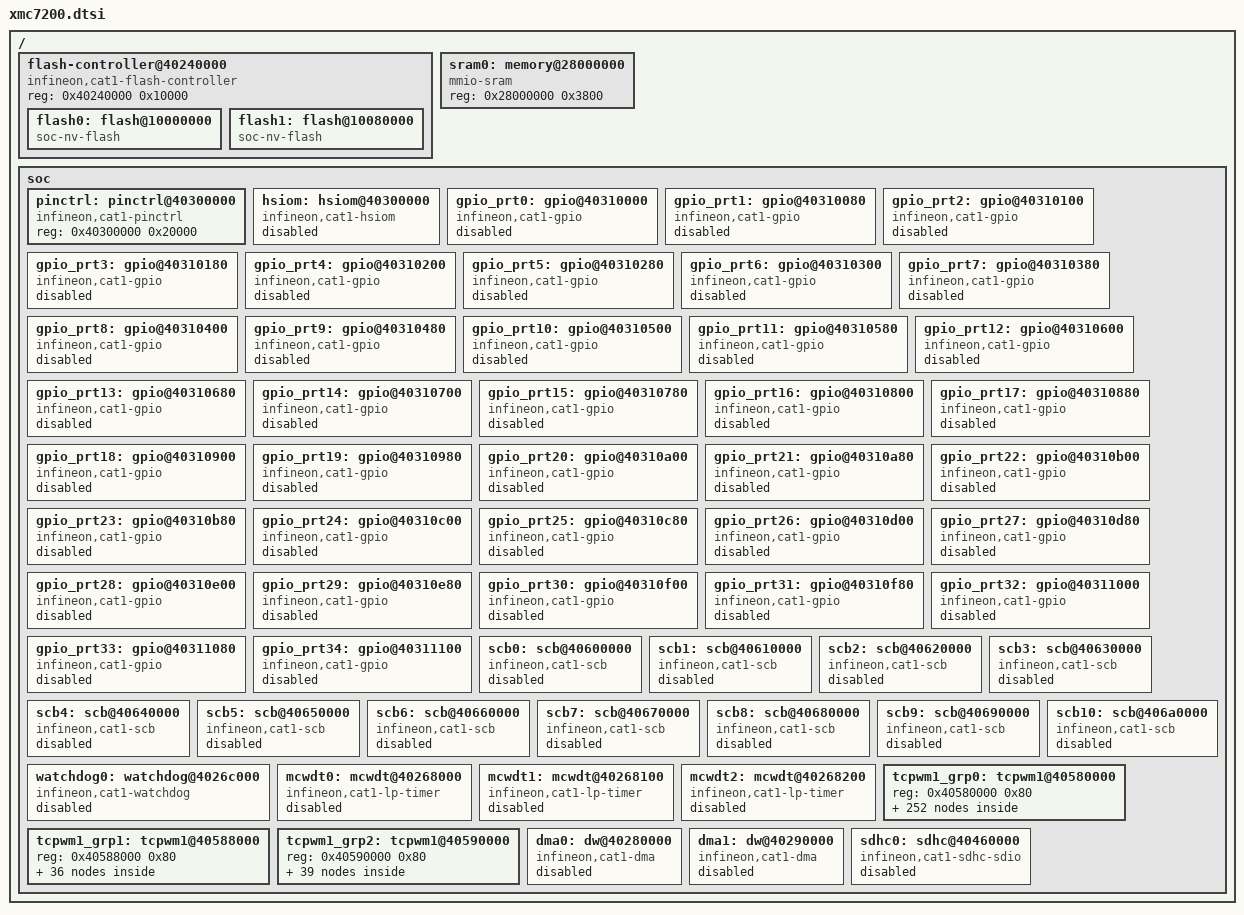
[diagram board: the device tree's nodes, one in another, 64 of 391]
/*
 * Copyright (c) 2023 Cypress Semiconductor Corporation (an Infineon company) or
 * an affiliate of Cypress Semiconductor Corporation
 *
 * SPDX-License-Identifier: Apache-2.0
 */

#include <mem.h>

/ {
	flash-controller@40240000 {
		compatible = "infineon,cat1-flash-controller";
		reg = <0x40240000 0x10000>;
		#address-cells = <1>;
		#size-cells = <1>;

		flash0: flash@10000000 {
			compatible = "soc-nv-flash";
			reg = <0x10000000 0x80000>;
			write-block-size = <512>;
			erase-block-size = <512>;
		};

		flash1: flash@10080000 {
			compatible = "soc-nv-flash";
			reg = <0x10080000 0x200000>;
			write-block-size = <512>;
			erase-block-size = <512>;
		};
	};

	/* 0x0000000028000800  _base_SRAM_CM0P =
	 * ((sram_base_address + sram_start_reserve) + sram_private_for_srom)
	 * TODO: Where better to keep srom private
	 */
	sram0: memory@28000000 {
		compatible = "mmio-sram";
		reg = <0x28000000 0x3800>;
	};

	soc {
		pinctrl: pinctrl@40300000 {
			compatible = "infineon,cat1-pinctrl";
			reg = <0x40300000 0x20000>;
		};

		hsiom: hsiom@40300000 {
			compatible = "infineon,cat1-hsiom";
			reg = <0x40300000 0x4000>;
			system-interrupts = <21 6>, <20 6>;
			status = "disabled";
		};

		gpio_prt0: gpio@40310000 {
			compatible = "infineon,cat1-gpio";
			reg = <0x40310000 0x80>;
			system-interrupts = <22 2>;
			gpio-controller;
			ngpios = <4>;
			status = "disabled";
			#gpio-cells = <2>;
		};

		gpio_prt1: gpio@40310080 {
			compatible = "infineon,cat1-gpio";
			reg = <0x40310080 0x80>;
			system-interrupts = <23 2>;
			gpio-controller;
			ngpios = <7>;
			status = "disabled";
			#gpio-cells = <2>;
		};

		gpio_prt2: gpio@40310100 {
			compatible = "infineon,cat1-gpio";
			reg = <0x40310100 0x80>;
			system-interrupts = <24 2>;
			gpio-controller;
			ngpios = <8>;
			status = "disabled";
			#gpio-cells = <2>;
		};

		gpio_prt3: gpio@40310180 {
			compatible = "infineon,cat1-gpio";
			reg = <0x40310180 0x80>;
			system-interrupts = <25 2>;
			gpio-controller;
			ngpios = <8>;
			status = "disabled";
			#gpio-cells = <2>;
		};

		gpio_prt4: gpio@40310200 {
			compatible = "infineon,cat1-gpio";
			reg = <0x40310200 0x80>;
			system-interrupts = <26 2>;
			gpio-controller;
			ngpios = <7>;
			status = "disabled";
			#gpio-cells = <2>;
		};

		gpio_prt5: gpio@40310280 {
			compatible = "infineon,cat1-gpio";
			reg = <0x40310280 0x80>;
			system-interrupts = <27 2>;
			gpio-controller;
			ngpios = <6>;
			status = "disabled";
			#gpio-cells = <2>;
		};

		gpio_prt6: gpio@40310300 {
			compatible = "infineon,cat1-gpio";
			reg = <0x40310300 0x80>;
			system-interrupts = <28 2>;
			gpio-controller;
			ngpios = <8>;
			status = "disabled";
			#gpio-cells = <2>;
		};

		gpio_prt7: gpio@40310380 {
			compatible = "infineon,cat1-gpio";
			reg = <0x40310380 0x80>;
			system-interrupts = <29 2>;
			gpio-controller;
			ngpios = <8>;
			status = "disabled";
			#gpio-cells = <2>;
		};

		gpio_prt8: gpio@40310400 {
			compatible = "infineon,cat1-gpio";
			reg = <0x40310400 0x80>;
			system-interrupts = <30 2>;
			gpio-controller;
			ngpios = <5>;
			status = "disabled";
			#gpio-cells = <2>;
		};

		gpio_prt9: gpio@40310480 {
			compatible = "infineon,cat1-gpio";
			reg = <0x40310480 0x80>;
			system-interrupts = <31 2>;
			gpio-controller;
			ngpios = <4>;
			status = "disabled";
			#gpio-cells = <2>;
		};

		gpio_prt10: gpio@40310500 {
			compatible = "infineon,cat1-gpio";
			reg = <0x40310500 0x80>;
			system-interrupts = <32 2>;
			gpio-controller;
			ngpios = <8>;
			status = "disabled";
			#gpio-cells = <2>;
		};

		gpio_prt11: gpio@40310580 {
			compatible = "infineon,cat1-gpio";
			reg = <0x40310580 0x80>;
			system-interrupts = <33 2>;
			gpio-controller;
			ngpios = <3>;
			status = "disabled";
			#gpio-cells = <2>;
		};

		gpio_prt12: gpio@40310600 {
			compatible = "infineon,cat1-gpio";
			reg = <0x40310600 0x80>;
			system-interrupts = <34 2>;
			gpio-controller;
			ngpios = <8>;
			status = "disabled";
			#gpio-cells = <2>;
		};

		gpio_prt13: gpio@40310680 {
			compatible = "infineon,cat1-gpio";
			reg = <0x40310680 0x80>;
			system-interrupts = <35 2>;
			gpio-controller;
			ngpios = <8>;
			status = "disabled";
			#gpio-cells = <2>;
		};

		gpio_prt14: gpio@40310700 {
			compatible = "infineon,cat1-gpio";
			reg = <0x40310700 0x80>;
			system-interrupts = <36 2>;
			gpio-controller;
			ngpios = <8>;
			status = "disabled";
			#gpio-cells = <2>;
		};

		gpio_prt15: gpio@40310780 {
			compatible = "infineon,cat1-gpio";
			reg = <0x40310780 0x80>;
			system-interrupts = <37 2>;
			gpio-controller;
			ngpios = <4>;
			status = "disabled";
			#gpio-cells = <2>;
		};

		gpio_prt16: gpio@40310800 {
			compatible = "infineon,cat1-gpio";
			reg = <0x40310800 0x80>;
			system-interrupts = <38 2>;
			gpio-controller;
			ngpios = <8>;
			status = "disabled";
			#gpio-cells = <2>;
		};

		gpio_prt17: gpio@40310880 {
			compatible = "infineon,cat1-gpio";
			reg = <0x40310880 0x80>;
			system-interrupts = <39 2>;
			gpio-controller;
			ngpios = <8>;
			status = "disabled";
			#gpio-cells = <2>;
		};

		gpio_prt18: gpio@40310900 {
			compatible = "infineon,cat1-gpio";
			reg = <0x40310900 0x80>;
			system-interrupts = <40 2>;
			gpio-controller;
			ngpios = <8>;
			status = "disabled";
			#gpio-cells = <2>;
		};

		gpio_prt19: gpio@40310980 {
			compatible = "infineon,cat1-gpio";
			reg = <0x40310980 0x80>;
			system-interrupts = <41 2>;
			gpio-controller;
			ngpios = <5>;
			status = "disabled";
			#gpio-cells = <2>;
		};

		gpio_prt20: gpio@40310a00 {
			compatible = "infineon,cat1-gpio";
			reg = <0x40310a00 0x80>;
			system-interrupts = <42 2>;
			gpio-controller;
			ngpios = <8>;
			status = "disabled";
			#gpio-cells = <2>;
		};

		gpio_prt21: gpio@40310a80 {
			compatible = "infineon,cat1-gpio";
			reg = <0x40310a80 0x80>;
			system-interrupts = <43 2>;
			gpio-controller;
			ngpios = <8>;
			status = "disabled";
			#gpio-cells = <2>;
		};

		gpio_prt22: gpio@40310b00 {
			compatible = "infineon,cat1-gpio";
			reg = <0x40310b00 0x80>;
			system-interrupts = <44 2>;
			gpio-controller;
			ngpios = <8>;
			status = "disabled";
			#gpio-cells = <2>;
		};

		gpio_prt23: gpio@40310b80 {
			compatible = "infineon,cat1-gpio";
			reg = <0x40310b80 0x80>;
			system-interrupts = <45 2>;
			gpio-controller;
			ngpios = <8>;
			status = "disabled";
			#gpio-cells = <2>;
		};

		gpio_prt24: gpio@40310c00 {
			compatible = "infineon,cat1-gpio";
			reg = <0x40310c00 0x80>;
			system-interrupts = <52 2>;
			gpio-controller;
			ngpios = <5>;
			status = "disabled";
			#gpio-cells = <2>;
		};

		gpio_prt25: gpio@40310c80 {
			compatible = "infineon,cat1-gpio";
			reg = <0x40310c80 0x80>;
			system-interrupts = <53 2>;
			gpio-controller;
			ngpios = <8>;
			status = "disabled";
			#gpio-cells = <2>;
		};

		gpio_prt26: gpio@40310d00 {
			compatible = "infineon,cat1-gpio";
			reg = <0x40310d00 0x80>;
			system-interrupts = <54 2>;
			gpio-controller;
			ngpios = <8>;
			status = "disabled";
			#gpio-cells = <2>;
		};

		gpio_prt27: gpio@40310d80 {
			compatible = "infineon,cat1-gpio";
			reg = <0x40310d80 0x80>;
			system-interrupts = <55 2>;
			gpio-controller;
			ngpios = <8>;
			status = "disabled";
			#gpio-cells = <2>;
		};

		gpio_prt28: gpio@40310e00 {
			compatible = "infineon,cat1-gpio";
			reg = <0x40310e00 0x80>;
			system-interrupts = <46 2>;
			gpio-controller;
			ngpios = <8>;
			status = "disabled";
			#gpio-cells = <2>;
		};

		gpio_prt29: gpio@40310e80 {
			compatible = "infineon,cat1-gpio";
			reg = <0x40310e80 0x80>;
			system-interrupts = <47 2>;
			gpio-controller;
			ngpios = <8>;
			status = "disabled";
			#gpio-cells = <2>;
		};

		gpio_prt30: gpio@40310f00 {
			compatible = "infineon,cat1-gpio";
			reg = <0x40310f00 0x80>;
			system-interrupts = <48 2>;
			gpio-controller;
			ngpios = <4>;
			status = "disabled";
			#gpio-cells = <2>;
		};

		gpio_prt31: gpio@40310f80 {
			compatible = "infineon,cat1-gpio";
			reg = <0x40310f80 0x80>;
			system-interrupts = <49 2>;
			gpio-controller;
			ngpios = <3>;
			status = "disabled";
			#gpio-cells = <2>;
		};

		gpio_prt32: gpio@40311000 {
			compatible = "infineon,cat1-gpio";
			reg = <0x40311000 0x80>;
			system-interrupts = <50 2>;
			gpio-controller;
			ngpios = <8>;
			status = "disabled";
			#gpio-cells = <2>;
		};

		gpio_prt33: gpio@40311080 {
			compatible = "infineon,cat1-gpio";
			reg = <0x40311080 0x80>;
			system-interrupts = <56 2>;
			gpio-controller;
			ngpios = <8>;
			status = "disabled";
			#gpio-cells = <2>;
		};

		gpio_prt34: gpio@40311100 {
			compatible = "infineon,cat1-gpio";
			reg = <0x40311100 0x80>;
			system-interrupts = <57 2>;
			gpio-controller;
			ngpios = <8>;
			status = "disabled";
			#gpio-cells = <2>;
		};

		scb0: scb@40600000 {
			compatible = "infineon,cat1-scb";
			reg = <0x40600000 0xfd0>;
			system-interrupts = <18 6>;
			status = "disabled";
		};

		scb1: scb@40610000 {
			compatible = "infineon,cat1-scb";
			reg = <0x40610000 0xfd0>;
			system-interrupts = <113 6>;
			status = "disabled";
		};

		scb2: scb@40620000 {
			compatible = "infineon,cat1-scb";
			reg = <0x40620000 0xfd0>;
			system-interrupts = <114 6>;
			status = "disabled";
		};

		scb3: scb@40630000 {
			compatible = "infineon,cat1-scb";
			reg = <0x40630000 0xfd0>;
			system-interrupts = <115 6>;
			status = "disabled";
		};

		scb4: scb@40640000 {
			compatible = "infineon,cat1-scb";
			reg = <0x40640000 0xfd0>;
			system-interrupts = <116 6>;
			status = "disabled";
		};

		scb5: scb@40650000 {
			compatible = "infineon,cat1-scb";
			reg = <0x40650000 0xfd0>;
			system-interrupts = <117 6>;
			status = "disabled";
		};

		scb6: scb@40660000 {
			compatible = "infineon,cat1-scb";
			reg = <0x40660000 0xfd0>;
			system-interrupts = <118 6>;
			status = "disabled";
		};

		scb7: scb@40670000 {
			compatible = "infineon,cat1-scb";
			reg = <0x40670000 0xfd0>;
			system-interrupts = <119 6>;
			status = "disabled";
		};

		scb8: scb@40680000 {
			compatible = "infineon,cat1-scb";
			reg = <0x40680000 0xfd0>;
			system-interrupts = <120 6>;
			status = "disabled";
		};

		scb9: scb@40690000 {
			compatible = "infineon,cat1-scb";
			reg = <0x40690000 0xfd0>;
			system-interrupts = <121 6>;
			status = "disabled";
		};

		scb10: scb@406a0000 {
			compatible = "infineon,cat1-scb";
			reg = <0x406a0000 0xfd0>;
			system-interrupts = <122 6>;
			status = "disabled";
		};

		watchdog0: watchdog@4026c000 {
			compatible = "infineon,cat1-watchdog";
			reg = <0x4026c000 0x80>;
			system-interrupts = <16 6>;
			status = "disabled";
		};

		mcwdt0: mcwdt@40268000 {
			compatible = "infineon,cat1-lp-timer";
			reg = <0x40268000 0x100>;
			system-interrupts = <13 6>;
			status = "disabled";
		};

		mcwdt1: mcwdt@40268100 {
			compatible = "infineon,cat1-lp-timer";
			reg = <0x40268100 0x100>;
			system-interrupts = <14 6>;
			status = "disabled";
		};

		mcwdt2: mcwdt@40268200 {
			compatible = "infineon,cat1-lp-timer";
			reg = <0x40268200 0x100>;
			system-interrupts = <15 6>;
			status = "disabled";
		};

		tcpwm1_grp0: tcpwm1@40580000 {
			reg = <0x40580000 0x80>;
			#address-cells = <1>;
			#size-cells = <1>;

			tcpwm0_0: tcpwm0_0@40580000 {
				compatible = "infineon,tcpwm";
				reg = <0x40580000 0x80>;
				resolution = <16>;
				status = "disabled";

				counter0_0: counter0_0 {
					compatible = "infineon,tcpwm-counter";
					system-interrupts = <435 6>;
					status = "disabled";
				};

				pwm0_0: pwm0_0 {
					compatible = "infineon,cat1-pwm";
					system-interrupts = <435 6>;
					#pwm-cells = <3>;
					status = "disabled";
				};
			};

			tcpwm0_1: tcpwm0_1@40580080 {
				compatible = "infineon,tcpwm";
				reg = <0x40580080 0x80>;
				resolution = <16>;
				status = "disabled";

				counter0_1: counter0_1 {
					compatible = "infineon,tcpwm-counter";
					system-interrupts = <436 6>;
					status = "disabled";
				};

				pwm0_1: pwm0_1 {
					compatible = "infineon,cat1-pwm";
					system-interrupts = <436 6>;
					#pwm-cells = <3>;
					status = "disabled";
				};
			};

			tcpwm0_2: tcpwm0_2@40580100 {
				compatible = "infineon,tcpwm";
				reg = <0x40580100 0x80>;
				resolution = <16>;
				status = "disabled";

				counter0_2: counter0_2 {
					compatible = "infineon,tcpwm-counter";
					system-interrupts = <437 6>;
					status = "disabled";
				};

				pwm0_2: pwm0_2 {
					compatible = "infineon,cat1-pwm";
					system-interrupts = <437 6>;
					#pwm-cells = <3>;
					status = "disabled";
				};
			};

			tcpwm0_3: tcpwm0_3@40580180 {
				compatible = "infineon,tcpwm";
				reg = <0x40580180 0x80>;
				resolution = <16>;
				status = "disabled";

				counter0_3: counter0_3 {
					compatible = "infineon,tcpwm-counter";
					system-interrupts = <438 6>;
					status = "disabled";
				};

				pwm0_3: pwm0_3 {
					compatible = "infineon,cat1-pwm";
					system-interrupts = <438 6>;
					#pwm-cells = <3>;
					status = "disabled";
				};
			};

			tcpwm0_4: tcpwm0_4@40580200 {
				compatible = "infineon,tcpwm";
				reg = <0x40580200 0x80>;
				resolution = <16>;
				status = "disabled";

				counter0_4: counter0_4 {
					compatible = "infineon,tcpwm-counter";
					system-interrupts = <439 6>;
					status = "disabled";
				};

				pwm0_4: pwm0_4 {
					compatible = "infineon,cat1-pwm";
					system-interrupts = <439 6>;
					#pwm-cells = <3>;
					status = "disabled";
				};
			};

			tcpwm0_5: tcpwm0_5@40580280 {
				compatible = "infineon,tcpwm";
				reg = <0x40580280 0x80>;
				resolution = <16>;
				status = "disabled";

				counter0_5: counter0_5 {
					compatible = "infineon,tcpwm-counter";
					system-interrupts = <440 6>;
					status = "disabled";
				};

				pwm0_5: pwm0_5 {
					compatible = "infineon,cat1-pwm";
					system-interrupts = <440 6>;
					#pwm-cells = <3>;
					status = "disabled";
				};
			};

			tcpwm0_6: tcpwm0_6@40580300 {
				compatible = "infineon,tcpwm";
				reg = <0x40580300 0x80>;
				resolution = <16>;
				status = "disabled";

				counter0_6: counter0_6 {
					compatible = "infineon,tcpwm-counter";
					system-interrupts = <441 6>;
					status = "disabled";
				};

				pwm0_6: pwm0_6 {
					compatible = "infineon,cat1-pwm";
					system-interrupts = <441 6>;
					#pwm-cells = <3>;
					status = "disabled";
				};
			};

			tcpwm0_7: tcpwm0_7@40580380 {
				compatible = "infineon,tcpwm";
				reg = <0x40580380 0x80>;
				resolution = <16>;
				status = "disabled";

				counter0_7: counter0_7 {
					compatible = "infineon,tcpwm-counter";
					system-interrupts = <442 6>;
					status = "disabled";
				};

				pwm0_7: pwm0_7 {
					compatible = "infineon,cat1-pwm";
					system-interrupts = <442 6>;
					#pwm-cells = <3>;
					status = "disabled";
				};
			};

			tcpwm0_8: tcpwm0_8@40580400 {
				compatible = "infineon,tcpwm";
				reg = <0x40580400 0x80>;
				resolution = <16>;
				status = "disabled";

				counter0_8: counter0_8 {
					compatible = "infineon,tcpwm-counter";
					system-interrupts = <443 6>;
					status = "disabled";
				};

				pwm0_8: pwm0_8 {
					compatible = "infineon,cat1-pwm";
					system-interrupts = <443 6>;
					#pwm-cells = <3>;
					status = "disabled";
				};
			};

			tcpwm0_9: tcpwm0_9@40580480 {
				compatible = "infineon,tcpwm";
				reg = <0x40580480 0x80>;
				resolution = <16>;
				status = "disabled";

				counter0_9: counter0_9 {
					compatible = "infineon,tcpwm-counter";
					system-interrupts = <444 6>;
					status = "disabled";
				};

				pwm0_9: pwm0_9 {
					compatible = "infineon,cat1-pwm";
					system-interrupts = <444 6>;
					#pwm-cells = <3>;
					status = "disabled";
				};
			};

			tcpwm0_10: tcpwm0_10@40580500 {
				compatible = "infineon,tcpwm";
				reg = <0x40580500 0x80>;
				resolution = <16>;
				status = "disabled";

				counter0_10: counter0_10 {
					compatible = "infineon,tcpwm-counter";
					system-interrupts = <445 6>;
					status = "disabled";
				};

				pwm0_10: pwm0_10 {
					compatible = "infineon,cat1-pwm";
					system-interrupts = <445 6>;
					#pwm-cells = <3>;
					status = "disabled";
				};
			};

			tcpwm0_11: tcpwm0_11@40580580 {
				compatible = "infineon,tcpwm";
				reg = <0x40580580 0x80>;
				resolution = <16>;
				status = "disabled";

				counter0_11: counter0_11 {
					compatible = "infineon,tcpwm-counter";
					system-interrupts = <446 6>;
					status = "disabled";
				};

				pwm0_11: pwm0_11 {
					compatible = "infineon,cat1-pwm";
					system-interrupts = <446 6>;
					#pwm-cells = <3>;
					status = "disabled";
				};
			};

			tcpwm0_12: tcpwm0_12@40580600 {
				compatible = "infineon,tcpwm";
				reg = <0x40580600 0x80>;
				resolution = <16>;
				status = "disabled";

				counter0_12: counter0_12 {
					compatible = "infineon,tcpwm-counter";
					system-interrupts = <447 6>;
					status = "disabled";
				};

				pwm0_12: pwm0_12 {
					compatible = "infineon,cat1-pwm";
					system-interrupts = <447 6>;
					#pwm-cells = <3>;
					status = "disabled";
				};
			};

			tcpwm0_13: tcpwm0_13@40580680 {
				compatible = "infineon,tcpwm";
				reg = <0x40580680 0x80>;
				resolution = <16>;
				status = "disabled";

				counter0_13: counter0_13 {
					compatible = "infineon,tcpwm-counter";
					system-interrupts = <448 6>;
					status = "disabled";
				};

				pwm0_13: pwm0_13 {
					compatible = "infineon,cat1-pwm";
					system-interrupts = <448 6>;
					#pwm-cells = <3>;
					status = "disabled";
				};
			};

			tcpwm0_14: tcpwm0_14@40580700 {
				compatible = "infineon,tcpwm";
				reg = <0x40580700 0x80>;
				resolution = <16>;
				status = "disabled";

				counter0_14: counter0_14 {
					compatible = "infineon,tcpwm-counter";
					system-interrupts = <449 6>;
					status = "disabled";
				};

				pwm0_14: pwm0_14 {
					compatible = "infineon,cat1-pwm";
					system-interrupts = <449 6>;
					#pwm-cells = <3>;
					status = "disabled";
				};
			};

			tcpwm0_15: tcpwm0_15@40580780 {
				compatible = "infineon,tcpwm";
				reg = <0x40580780 0x80>;
				resolution = <16>;
				status = "disabled";

				counter0_15: counter0_15 {
					compatible = "infineon,tcpwm-counter";
					system-interrupts = <450 6>;
					status = "disabled";
				};

				pwm0_15: pwm0_15 {
					compatible = "infineon,cat1-pwm";
					system-interrupts = <450 6>;
					#pwm-cells = <3>;
					status = "disabled";
				};
			};

			tcpwm0_16: tcpwm0_16@40580800 {
				compatible = "infineon,tcpwm";
				reg = <0x40580800 0x80>;
				resolution = <16>;
				status = "disabled";

				counter0_16: counter0_16 {
					compatible = "infineon,tcpwm-counter";
					system-interrupts = <451 6>;
					status = "disabled";
				};

				pwm0_16: pwm0_16 {
					compatible = "infineon,cat1-pwm";
					system-interrupts = <451 6>;
					#pwm-cells = <3>;
					status = "disabled";
				};
			};

			tcpwm0_17: tcpwm0_17@40580880 {
				compatible = "infineon,tcpwm";
				reg = <0x40580880 0x80>;
				resolution = <16>;
				status = "disabled";

				counter0_17: counter0_17 {
					compatible = "infineon,tcpwm-counter";
					system-interrupts = <452 6>;
					status = "disabled";
				};

				pwm0_17: pwm0_17 {
					compatible = "infineon,cat1-pwm";
					system-interrupts = <452 6>;
					#pwm-cells = <3>;
					status = "disabled";
				};
			};

			tcpwm0_18: tcpwm0_18@40580900 {
				compatible = "infineon,tcpwm";
				reg = <0x40580900 0x80>;
				resolution = <16>;
				status = "disabled";

				counter0_18: counter0_18 {
					compatible = "infineon,tcpwm-counter";
					system-interrupts = <453 6>;
					status = "disabled";
				};

				pwm0_18: pwm0_18 {
					compatible = "infineon,cat1-pwm";
					system-interrupts = <453 6>;
					#pwm-cells = <3>;
					status = "disabled";
				};
			};

			tcpwm0_19: tcpwm0_19@40580980 {
				compatible = "infineon,tcpwm";
				reg = <0x40580980 0x80>;
				resolution = <16>;
				status = "disabled";

				counter0_19: counter0_19 {
					compatible = "infineon,tcpwm-counter";
					system-interrupts = <454 6>;
					status = "disabled";
				};

				pwm0_19: pwm0_19 {
					compatible = "infineon,cat1-pwm";
					system-interrupts = <454 6>;
					#pwm-cells = <3>;
					status = "disabled";
				};
			};

			tcpwm0_20: tcpwm0_20@40580a00 {
				compatible = "infineon,tcpwm";
				reg = <0x40580a00 0x80>;
				resolution = <16>;
				status = "disabled";

				counter0_20: counter0_20 {
					compatible = "infineon,tcpwm-counter";
					system-interrupts = <455 6>;
					status = "disabled";
				};

				pwm0_20: pwm0_20 {
					compatible = "infineon,cat1-pwm";
					system-interrupts = <455 6>;
					#pwm-cells = <3>;
					status = "disabled";
				};
			};

			tcpwm0_21: tcpwm0_21@40580a80 {
				compatible = "infineon,tcpwm";
				reg = <0x40580a80 0x80>;
				resolution = <16>;
				status = "disabled";

				counter0_21: counter0_21 {
					compatible = "infineon,tcpwm-counter";
					system-interrupts = <456 6>;
					status = "disabled";
				};

				pwm0_21: pwm0_21 {
					compatible = "infineon,cat1-pwm";
					system-interrupts = <456 6>;
					#pwm-cells = <3>;
					status = "disabled";
				};
			};

			tcpwm0_22: tcpwm0_22@40580b00 {
				compatible = "infineon,tcpwm";
				reg = <0x40580b00 0x80>;
				resolution = <16>;
				status = "disabled";

				counter0_22: counter0_22 {
					compatible = "infineon,tcpwm-counter";
					system-interrupts = <457 6>;
					status = "disabled";
				};

				pwm0_22: pwm0_22 {
					compatible = "infineon,cat1-pwm";
					system-interrupts = <457 6>;
					#pwm-cells = <3>;
					status = "disabled";
				};
			};

			tcpwm0_23: tcpwm0_23@40580b80 {
				compatible = "infineon,tcpwm";
				reg = <0x40580b80 0x80>;
				resolution = <16>;
				status = "disabled";

				counter0_23: counter0_23 {
					compatible = "infineon,tcpwm-counter";
					system-interrupts = <458 6>;
					status = "disabled";
				};

				pwm0_23: pwm0_23 {
					compatible = "infineon,cat1-pwm";
					system-interrupts = <458 6>;
					#pwm-cells = <3>;
					status = "disabled";
				};
			};

			tcpwm0_24: tcpwm0_24@40580c00 {
				compatible = "infineon,tcpwm";
				reg = <0x40580c00 0x80>;
				resolution = <16>;
				status = "disabled";

				counter0_24: counter0_24 {
					compatible = "infineon,tcpwm-counter";
					system-interrupts = <459 6>;
					status = "disabled";
				};

				pwm0_24: pwm0_24 {
					compatible = "infineon,cat1-pwm";
					system-interrupts = <459 6>;
					#pwm-cells = <3>;
					status = "disabled";
				};
			};

			tcpwm0_25: tcpwm0_25@40580c80 {
				compatible = "infineon,tcpwm";
				reg = <0x40580c80 0x80>;
				resolution = <16>;
				status = "disabled";

				counter0_25: counter0_25 {
					compatible = "infineon,tcpwm-counter";
					system-interrupts = <460 6>;
					status = "disabled";
				};

				pwm0_25: pwm0_25 {
					compatible = "infineon,cat1-pwm";
					system-interrupts = <460 6>;
					#pwm-cells = <3>;
					status = "disabled";
				};
			};

			tcpwm0_26: tcpwm0_26@40580d00 {
				compatible = "infineon,tcpwm";
				reg = <0x40580d00 0x80>;
				resolution = <16>;
				status = "disabled";

				counter0_26: counter0_26 {
					compatible = "infineon,tcpwm-counter";
					system-interrupts = <461 6>;
					status = "disabled";
				};

				pwm0_26: pwm0_26 {
					compatible = "infineon,cat1-pwm";
					system-interrupts = <461 6>;
					#pwm-cells = <3>;
					status = "disabled";
				};
			};

			tcpwm0_27: tcpwm0_27@40580d80 {
				compatible = "infineon,tcpwm";
				reg = <0x40580d80 0x80>;
				resolution = <16>;
				status = "disabled";

				counter0_27: counter0_27 {
					compatible = "infineon,tcpwm-counter";
					system-interrupts = <462 6>;
					status = "disabled";
				};

				pwm0_27: pwm0_27 {
					compatible = "infineon,cat1-pwm";
					system-interrupts = <462 6>;
					#pwm-cells = <3>;
					status = "disabled";
				};
			};

			tcpwm0_28: tcpwm0_28@40580e00 {
				compatible = "infineon,tcpwm";
				reg = <0x40580e00 0x80>;
				resolution = <16>;
				status = "disabled";

				counter0_28: counter0_28 {
					compatible = "infineon,tcpwm-counter";
					system-interrupts = <463 6>;
					status = "disabled";
				};

				pwm0_28: pwm0_28 {
					compatible = "infineon,cat1-pwm";
					system-interrupts = <463 6>;
					#pwm-cells = <3>;
					status = "disabled";
				};
			};

			tcpwm0_29: tcpwm0_29@40580e80 {
				compatible = "infineon,tcpwm";
				reg = <0x40580e80 0x80>;
				resolution = <16>;
				status = "disabled";

				counter0_29: counter0_29 {
					compatible = "infineon,tcpwm-counter";
					system-interrupts = <464 6>;
					status = "disabled";
				};

				pwm0_29: pwm0_29 {
					compatible = "infineon,cat1-pwm";
					system-interrupts = <464 6>;
					#pwm-cells = <3>;
					status = "disabled";
				};
			};

			tcpwm0_30: tcpwm0_30@40580f00 {
				compatible = "infineon,tcpwm";
				reg = <0x40580f00 0x80>;
				resolution = <16>;
				status = "disabled";

				counter0_30: counter0_30 {
					compatible = "infineon,tcpwm-counter";
					system-interrupts = <465 6>;
					status = "disabled";
				};

				pwm0_30: pwm0_30 {
					compatible = "infineon,cat1-pwm";
					system-interrupts = <465 6>;
					#pwm-cells = <3>;
					status = "disabled";
				};
			};

			tcpwm0_31: tcpwm0_31@40580f80 {
				compatible = "infineon,tcpwm";
				reg = <0x40580f80 0x80>;
				resolution = <16>;
				status = "disabled";

				counter0_31: counter0_31 {
					compatible = "infineon,tcpwm-counter";
					system-interrupts = <466 6>;
					status = "disabled";
				};

				pwm0_31: pwm0_31 {
					compatible = "infineon,cat1-pwm";
					system-interrupts = <466 6>;
					#pwm-cells = <3>;
					status = "disabled";
				};
			};

			tcpwm0_32: tcpwm0_32@40581000 {
				compatible = "infineon,tcpwm";
				reg = <0x40581000 0x80>;
				resolution = <16>;
				status = "disabled";

				counter0_32: counter0_32 {
					compatible = "infineon,tcpwm-counter";
					system-interrupts = <467 6>;
					status = "disabled";
				};

				pwm0_32: pwm0_32 {
					compatible = "infineon,cat1-pwm";
					system-interrupts = <467 6>;
					#pwm-cells = <3>;
					status = "disabled";
				};
			};

			tcpwm0_33: tcpwm0_33@40581080 {
				compatible = "infineon,tcpwm";
				reg = <0x40581080 0x80>;
				resolution = <16>;
				status = "disabled";

				counter0_33: counter0_33 {
					compatible = "infineon,tcpwm-counter";
					system-interrupts = <468 6>;
					status = "disabled";
				};

				pwm0_33: pwm0_33 {
					compatible = "infineon,cat1-pwm";
					system-interrupts = <468 6>;
					#pwm-cells = <3>;
					status = "disabled";
				};
			};

			tcpwm0_34: tcpwm0_34@40581100 {
				compatible = "infineon,tcpwm";
				reg = <0x40581100 0x80>;
				resolution = <16>;
				status = "disabled";

				counter0_34: counter0_34 {
					compatible = "infineon,tcpwm-counter";
					system-interrupts = <469 6>;
					status = "disabled";
				};

				pwm0_34: pwm0_34 {
					compatible = "infineon,cat1-pwm";
					system-interrupts = <469 6>;
					#pwm-cells = <3>;
					status = "disabled";
				};
			};

			tcpwm0_35: tcpwm0_35@40581180 {
				compatible = "infineon,tcpwm";
				reg = <0x40581180 0x80>;
				resolution = <16>;
				status = "disabled";

				counter0_35: counter0_35 {
					compatible = "infineon,tcpwm-counter";
					system-interrupts = <470 6>;
					status = "disabled";
				};

				pwm0_35: pwm0_35 {
					compatible = "infineon,cat1-pwm";
					system-interrupts = <470 6>;
					#pwm-cells = <3>;
					status = "disabled";
				};
			};

			tcpwm0_36: tcpwm0_36@40581200 {
				compatible = "infineon,tcpwm";
				reg = <0x40581200 0x80>;
				resolution = <16>;
				status = "disabled";

				counter0_36: counter0_36 {
					compatible = "infineon,tcpwm-counter";
					system-interrupts = <471 6>;
					status = "disabled";
				};

				pwm0_36: pwm0_36 {
					compatible = "infineon,cat1-pwm";
					system-interrupts = <471 6>;
					#pwm-cells = <3>;
					status = "disabled";
				};
			};

			tcpwm0_37: tcpwm0_37@40581280 {
				compatible = "infineon,tcpwm";
				reg = <0x40581280 0x80>;
				resolution = <16>;
				status = "disabled";

				counter0_37: counter0_37 {
					compatible = "infineon,tcpwm-counter";
					system-interrupts = <472 6>;
					status = "disabled";
				};

				pwm0_37: pwm0_37 {
					compatible = "infineon,cat1-pwm";
					system-interrupts = <472 6>;
					#pwm-cells = <3>;
					status = "disabled";
				};
			};

			tcpwm0_38: tcpwm0_38@40581300 {
				compatible = "infineon,tcpwm";
				reg = <0x40581300 0x80>;
				resolution = <16>;
				status = "disabled";

				counter0_38: counter0_38 {
					compatible = "infineon,tcpwm-counter";
					system-interrupts = <473 6>;
					status = "disabled";
				};

				pwm0_38: pwm0_38 {
					compatible = "infineon,cat1-pwm";
					system-interrupts = <473 6>;
					#pwm-cells = <3>;
					status = "disabled";
				};
			};

			tcpwm0_39: tcpwm0_39@40581380 {
				compatible = "infineon,tcpwm";
				reg = <0x40581380 0x80>;
				resolution = <16>;
				status = "disabled";

				counter0_39: counter0_39 {
					compatible = "infineon,tcpwm-counter";
					system-interrupts = <474 6>;
					status = "disabled";
				};

				pwm0_39: pwm0_39 {
					compatible = "infineon,cat1-pwm";
					system-interrupts = <474 6>;
					#pwm-cells = <3>;
					status = "disabled";
				};
			};

			tcpwm0_40: tcpwm0_40@40581400 {
				compatible = "infineon,tcpwm";
				reg = <0x40581400 0x80>;
				resolution = <16>;
				status = "disabled";

				counter0_40: counter0_40 {
					compatible = "infineon,tcpwm-counter";
					system-interrupts = <475 6>;
					status = "disabled";
				};

				pwm0_40: pwm0_40 {
					compatible = "infineon,cat1-pwm";
					system-interrupts = <475 6>;
					#pwm-cells = <3>;
					status = "disabled";
				};
			};

			tcpwm0_41: tcpwm0_41@40581480 {
				compatible = "infineon,tcpwm";
				reg = <0x40581480 0x80>;
				resolution = <16>;
				status = "disabled";

				counter0_41: counter0_41 {
					compatible = "infineon,tcpwm-counter";
					system-interrupts = <476 6>;
					status = "disabled";
				};

				pwm0_41: pwm0_41 {
					compatible = "infineon,cat1-pwm";
					system-interrupts = <476 6>;
					#pwm-cells = <3>;
					status = "disabled";
				};
			};

			tcpwm0_42: tcpwm0_42@40581500 {
				compatible = "infineon,tcpwm";
				reg = <0x40581500 0x80>;
				resolution = <16>;
				status = "disabled";

				counter0_42: counter0_42 {
					compatible = "infineon,tcpwm-counter";
					system-interrupts = <477 6>;
					status = "disabled";
				};

				pwm0_42: pwm0_42 {
					compatible = "infineon,cat1-pwm";
					system-interrupts = <477 6>;
					#pwm-cells = <3>;
					status = "disabled";
				};
			};

			tcpwm0_43: tcpwm0_43@40581580 {
				compatible = "infineon,tcpwm";
				reg = <0x40581580 0x80>;
				resolution = <16>;
				status = "disabled";

				counter0_43: counter0_43 {
					compatible = "infineon,tcpwm-counter";
					system-interrupts = <478 6>;
					status = "disabled";
				};

				pwm0_43: pwm0_43 {
					compatible = "infineon,cat1-pwm";
					system-interrupts = <478 6>;
					#pwm-cells = <3>;
					status = "disabled";
				};
			};

			tcpwm0_44: tcpwm0_44@40581600 {
				compatible = "infineon,tcpwm";
				reg = <0x40581600 0x80>;
				resolution = <16>;
				status = "disabled";

				counter0_44: counter0_44 {
					compatible = "infineon,tcpwm-counter";
					system-interrupts = <479 6>;
					status = "disabled";
				};

				pwm0_44: pwm0_44 {
					compatible = "infineon,cat1-pwm";
					system-interrupts = <479 6>;
					#pwm-cells = <3>;
					status = "disabled";
				};
			};

			tcpwm0_45: tcpwm0_45@40581680 {
				compatible = "infineon,tcpwm";
				reg = <0x40581680 0x80>;
				resolution = <16>;
				status = "disabled";

				counter0_45: counter0_45 {
					compatible = "infineon,tcpwm-counter";
					system-interrupts = <480 6>;
					status = "disabled";
				};

				pwm0_45: pwm0_45 {
					compatible = "infineon,cat1-pwm";
					system-interrupts = <480 6>;
					#pwm-cells = <3>;
					status = "disabled";
				};
			};

			tcpwm0_46: tcpwm0_46@40581700 {
				compatible = "infineon,tcpwm";
				reg = <0x40581700 0x80>;
				resolution = <16>;
				status = "disabled";

				counter0_46: counter0_46 {
					compatible = "infineon,tcpwm-counter";
					system-interrupts = <481 6>;
					status = "disabled";
				};

				pwm0_46: pwm0_46 {
					compatible = "infineon,cat1-pwm";
					system-interrupts = <481 6>;
					#pwm-cells = <3>;
					status = "disabled";
				};
			};

			tcpwm0_47: tcpwm0_47@40581780 {
				compatible = "infineon,tcpwm";
				reg = <0x40581780 0x80>;
				resolution = <16>;
				status = "disabled";

				counter0_47: counter0_47 {
					compatible = "infineon,tcpwm-counter";
					system-interrupts = <482 6>;
					status = "disabled";
				};

				pwm0_47: pwm0_47 {
					compatible = "infineon,cat1-pwm";
					system-interrupts = <482 6>;
					#pwm-cells = <3>;
					status = "disabled";
				};
			};

			tcpwm0_48: tcpwm0_48@40581800 {
				compatible = "infineon,tcpwm";
				reg = <0x40581800 0x80>;
				resolution = <16>;
				status = "disabled";

				counter0_48: counter0_48 {
					compatible = "infineon,tcpwm-counter";
					system-interrupts = <483 6>;
					status = "disabled";
				};

				pwm0_48: pwm0_48 {
					compatible = "infineon,cat1-pwm";
					system-interrupts = <483 6>;
					#pwm-cells = <3>;
					status = "disabled";
				};
			};

			tcpwm0_49: tcpwm0_49@40581880 {
				compatible = "infineon,tcpwm";
				reg = <0x40581880 0x80>;
				resolution = <16>;
				status = "disabled";

				counter0_49: counter0_49 {
					compatible = "infineon,tcpwm-counter";
					system-interrupts = <484 6>;
					status = "disabled";
				};

				pwm0_49: pwm0_49 {
					compatible = "infineon,cat1-pwm";
					system-interrupts = <484 6>;
					#pwm-cells = <3>;
					status = "disabled";
				};
			};

			tcpwm0_50: tcpwm0_50@40581900 {
				compatible = "infineon,tcpwm";
				reg = <0x40581900 0x80>;
				resolution = <16>;
				status = "disabled";

				counter0_50: counter0_50 {
					compatible = "infineon,tcpwm-counter";
					system-interrupts = <485 6>;
					status = "disabled";
				};

				pwm0_50: pwm0_50 {
					compatible = "infineon,cat1-pwm";
					system-interrupts = <485 6>;
					#pwm-cells = <3>;
					status = "disabled";
				};
			};

			tcpwm0_51: tcpwm0_51@40581980 {
				compatible = "infineon,tcpwm";
				reg = <0x40581980 0x80>;
				resolution = <16>;
				status = "disabled";

				counter0_51: counter0_51 {
					compatible = "infineon,tcpwm-counter";
					system-interrupts = <486 6>;
					status = "disabled";
				};

				pwm0_51: pwm0_51 {
					compatible = "infineon,cat1-pwm";
					system-interrupts = <486 6>;
					#pwm-cells = <3>;
					status = "disabled";
				};
			};

			tcpwm0_52: tcpwm0_52@40581a00 {
				compatible = "infineon,tcpwm";
				reg = <0x40581a00 0x80>;
				resolution = <16>;
				status = "disabled";

				counter0_52: counter0_52 {
					compatible = "infineon,tcpwm-counter";
					system-interrupts = <487 6>;
					status = "disabled";
				};

				pwm0_52: pwm0_52 {
					compatible = "infineon,cat1-pwm";
					system-interrupts = <487 6>;
					#pwm-cells = <3>;
					status = "disabled";
				};
			};

			tcpwm0_53: tcpwm0_53@40581a80 {
				compatible = "infineon,tcpwm";
				reg = <0x40581a80 0x80>;
				resolution = <16>;
				status = "disabled";

				counter0_53: counter0_53 {
					compatible = "infineon,tcpwm-counter";
					system-interrupts = <488 6>;
					status = "disabled";
				};

				pwm0_53: pwm0_53 {
					compatible = "infineon,cat1-pwm";
					system-interrupts = <488 6>;
					#pwm-cells = <3>;
					status = "disabled";
				};
			};

			tcpwm0_54: tcpwm0_54@40581b00 {
				compatible = "infineon,tcpwm";
				reg = <0x40581b00 0x80>;
				resolution = <16>;
				status = "disabled";

				counter0_54: counter0_54 {
					compatible = "infineon,tcpwm-counter";
					system-interrupts = <489 6>;
					status = "disabled";
				};

				pwm0_54: pwm0_54 {
					compatible = "infineon,cat1-pwm";
					system-interrupts = <489 6>;
					#pwm-cells = <3>;
					status = "disabled";
				};
			};

			tcpwm0_55: tcpwm0_55@40581b80 {
				compatible = "infineon,tcpwm";
				reg = <0x40581b80 0x80>;
				resolution = <16>;
				status = "disabled";

				counter0_55: counter0_55 {
					compatible = "infineon,tcpwm-counter";
					system-interrupts = <490 6>;
					status = "disabled";
				};

				pwm0_55: pwm0_55 {
					compatible = "infineon,cat1-pwm";
					system-interrupts = <490 6>;
					#pwm-cells = <3>;
					status = "disabled";
				};
			};

			tcpwm0_56: tcpwm0_56@40581c00 {
				compatible = "infineon,tcpwm";
				reg = <0x40581c00 0x80>;
				resolution = <16>;
				status = "disabled";

				counter0_56: counter0_56 {
					compatible = "infineon,tcpwm-counter";
					system-interrupts = <491 6>;
					status = "disabled";
				};

				pwm0_56: pwm0_56 {
					compatible = "infineon,cat1-pwm";
					system-interrupts = <491 6>;
					#pwm-cells = <3>;
					status = "disabled";
				};
			};

			tcpwm0_57: tcpwm0_57@40581c80 {
				compatible = "infineon,tcpwm";
				reg = <0x40581c80 0x80>;
				resolution = <16>;
				status = "disabled";

				counter0_57: counter0_57 {
					compatible = "infineon,tcpwm-counter";
					system-interrupts = <492 6>;
					status = "disabled";
				};

				pwm0_57: pwm0_57 {
					compatible = "infineon,cat1-pwm";
					system-interrupts = <492 6>;
					#pwm-cells = <3>;
					status = "disabled";
				};
			};

			tcpwm0_58: tcpwm0_58@40581d00 {
				compatible = "infineon,tcpwm";
				reg = <0x40581d00 0x80>;
				resolution = <16>;
				status = "disabled";

				counter0_58: counter0_58 {
					compatible = "infineon,tcpwm-counter";
					system-interrupts = <493 6>;
					status = "disabled";
				};

				pwm0_58: pwm0_58 {
					compatible = "infineon,cat1-pwm";
					system-interrupts = <493 6>;
					#pwm-cells = <3>;
					status = "disabled";
				};
			};

			tcpwm0_59: tcpwm0_59@40581d80 {
				compatible = "infineon,tcpwm";
				reg = <0x40581d80 0x80>;
				resolution = <16>;
				status = "disabled";

				counter0_59: counter0_59 {
					compatible = "infineon,tcpwm-counter";
					system-interrupts = <494 6>;
					status = "disabled";
				};

				pwm0_59: pwm0_59 {
					compatible = "infineon,cat1-pwm";
					system-interrupts = <494 6>;
					#pwm-cells = <3>;
					status = "disabled";
				};
			};

			tcpwm0_60: tcpwm0_60@40581e00 {
				compatible = "infineon,tcpwm";
				reg = <0x40581e00 0x80>;
				resolution = <16>;
				status = "disabled";

				counter0_60: counter0_60 {
					compatible = "infineon,tcpwm-counter";
					system-interrupts = <495 6>;
					status = "disabled";
				};

				pwm0_60: pwm0_60 {
					compatible = "infineon,cat1-pwm";
					system-interrupts = <495 6>;
					#pwm-cells = <3>;
					status = "disabled";
				};
			};

			tcpwm0_61: tcpwm0_61@40581e80 {
				compatible = "infineon,tcpwm";
				reg = <0x40581e80 0x80>;
				resolution = <16>;
				status = "disabled";

				counter0_61: counter0_61 {
					compatible = "infineon,tcpwm-counter";
					system-interrupts = <496 6>;
					status = "disabled";
				};

				pwm0_61: pwm0_61 {
					compatible = "infineon,cat1-pwm";
					system-interrupts = <496 6>;
					#pwm-cells = <3>;
					status = "disabled";
				};
			};

			tcpwm0_62: tcpwm0_62@40581f00 {
				compatible = "infineon,tcpwm";
				reg = <0x40581f00 0x80>;
				resolution = <16>;
				status = "disabled";

				counter0_62: counter0_62 {
					compatible = "infineon,tcpwm-counter";
					system-interrupts = <497 6>;
					status = "disabled";
				};

				pwm0_62: pwm0_62 {
					compatible = "infineon,cat1-pwm";
					system-interrupts = <497 6>;
					#pwm-cells = <3>;
					status = "disabled";
				};
			};

			tcpwm0_63: tcpwm0_63@40581f80 {
				compatible = "infineon,tcpwm";
				reg = <0x40581f80 0x80>;
				resolution = <16>;
				status = "disabled";

				counter0_63: counter0_63 {
					compatible = "infineon,tcpwm-counter";
					system-interrupts = <498 6>;
					status = "disabled";
				};

				pwm0_63: pwm0_63 {
					compatible = "infineon,cat1-pwm";
					system-interrupts = <498 6>;
					#pwm-cells = <3>;
					status = "disabled";
				};
			};

			tcpwm0_64: tcpwm0_64@40582000 {
				compatible = "infineon,tcpwm";
				reg = <0x40582000 0x80>;
				resolution = <16>;
				status = "disabled";

				counter0_64: counter0_64 {
					compatible = "infineon,tcpwm-counter";
					system-interrupts = <499 6>;
					status = "disabled";
				};

				pwm0_64: pwm0_64 {
					compatible = "infineon,cat1-pwm";
					system-interrupts = <499 6>;
					#pwm-cells = <3>;
					status = "disabled";
				};
			};

			tcpwm0_65: tcpwm0_65@40582080 {
				compatible = "infineon,tcpwm";
				reg = <0x40582080 0x80>;
				resolution = <16>;
				status = "disabled";

				counter0_65: counter0_65 {
					compatible = "infineon,tcpwm-counter";
					system-interrupts = <500 6>;
					status = "disabled";
				};

				pwm0_65: pwm0_65 {
					compatible = "infineon,cat1-pwm";
					system-interrupts = <500 6>;
					#pwm-cells = <3>;
					status = "disabled";
				};
			};

			tcpwm0_66: tcpwm0_66@40582100 {
				compatible = "infineon,tcpwm";
				reg = <0x40582100 0x80>;
				resolution = <16>;
				status = "disabled";

				counter0_66: counter0_66 {
					compatible = "infineon,tcpwm-counter";
					system-interrupts = <501 6>;
					status = "disabled";
				};

				pwm0_66: pwm0_66 {
					compatible = "infineon,cat1-pwm";
					system-interrupts = <501 6>;
					#pwm-cells = <3>;
					status = "disabled";
				};
			};

			tcpwm0_67: tcpwm0_67@40582180 {
				compatible = "infineon,tcpwm";
				reg = <0x40582180 0x80>;
				resolution = <16>;
				status = "disabled";

				counter0_67: counter0_67 {
					compatible = "infineon,tcpwm-counter";
					system-interrupts = <502 6>;
					status = "disabled";
				};

				pwm0_67: pwm0_67 {
					compatible = "infineon,cat1-pwm";
					system-interrupts = <502 6>;
					#pwm-cells = <3>;
					status = "disabled";
				};
			};

			tcpwm0_68: tcpwm0_68@40582200 {
				compatible = "infineon,tcpwm";
				reg = <0x40582200 0x80>;
				resolution = <16>;
				status = "disabled";

				counter0_68: counter0_68 {
					compatible = "infineon,tcpwm-counter";
					system-interrupts = <503 6>;
					status = "disabled";
				};

				pwm0_68: pwm0_68 {
					compatible = "infineon,cat1-pwm";
					system-interrupts = <503 6>;
					#pwm-cells = <3>;
					status = "disabled";
				};
			};

			tcpwm0_69: tcpwm0_69@40582280 {
				compatible = "infineon,tcpwm";
				reg = <0x40582280 0x80>;
				resolution = <16>;
				status = "disabled";

				counter0_69: counter0_69 {
					compatible = "infineon,tcpwm-counter";
					system-interrupts = <504 6>;
					status = "disabled";
				};

				pwm0_69: pwm0_69 {
					compatible = "infineon,cat1-pwm";
					system-interrupts = <504 6>;
					#pwm-cells = <3>;
					status = "disabled";
				};
			};

			tcpwm0_70: tcpwm0_70@40582300 {
				compatible = "infineon,tcpwm";
				reg = <0x40582300 0x80>;
				resolution = <16>;
				status = "disabled";

				counter0_70: counter0_70 {
					compatible = "infineon,tcpwm-counter";
					system-interrupts = <505 6>;
					status = "disabled";
				};

				pwm0_70: pwm0_70 {
					compatible = "infineon,cat1-pwm";
					system-interrupts = <505 6>;
					#pwm-cells = <3>;
					status = "disabled";
				};
			};

			tcpwm0_71: tcpwm0_71@40582380 {
				compatible = "infineon,tcpwm";
				reg = <0x40582380 0x80>;
				resolution = <16>;
				status = "disabled";

				counter0_71: counter0_71 {
					compatible = "infineon,tcpwm-counter";
					system-interrupts = <506 6>;
					status = "disabled";
				};

				pwm0_71: pwm0_71 {
					compatible = "infineon,cat1-pwm";
					system-interrupts = <506 6>;
					#pwm-cells = <3>;
					status = "disabled";
				};
			};

			tcpwm0_72: tcpwm0_72@40582400 {
				compatible = "infineon,tcpwm";
				reg = <0x40582400 0x80>;
				resolution = <16>;
				status = "disabled";

				counter0_72: counter0_72 {
					compatible = "infineon,tcpwm-counter";
					system-interrupts = <507 6>;
					status = "disabled";
				};

				pwm0_72: pwm0_72 {
					compatible = "infineon,cat1-pwm";
					system-interrupts = <507 6>;
					#pwm-cells = <3>;
					status = "disabled";
				};
			};

			tcpwm0_73: tcpwm0_73@40582480 {
				compatible = "infineon,tcpwm";
				reg = <0x40582480 0x80>;
				resolution = <16>;
				status = "disabled";

				counter0_73: counter0_73 {
					compatible = "infineon,tcpwm-counter";
					system-interrupts = <508 6>;
					status = "disabled";
				};

				pwm0_73: pwm0_73 {
					compatible = "infineon,cat1-pwm";
					system-interrupts = <508 6>;
					#pwm-cells = <3>;
					status = "disabled";
				};
			};

			tcpwm0_74: tcpwm0_74@40582500 {
				compatible = "infineon,tcpwm";
				reg = <0x40582500 0x80>;
				resolution = <16>;
				status = "disabled";

				counter0_74: counter0_74 {
					compatible = "infineon,tcpwm-counter";
					system-interrupts = <509 6>;
					status = "disabled";
				};

				pwm0_74: pwm0_74 {
					compatible = "infineon,cat1-pwm";
					system-interrupts = <509 6>;
					#pwm-cells = <3>;
					status = "disabled";
				};
			};

			tcpwm0_75: tcpwm0_75@40582580 {
				compatible = "infineon,tcpwm";
				reg = <0x40582580 0x80>;
				resolution = <16>;
				status = "disabled";

				counter0_75: counter0_75 {
					compatible = "infineon,tcpwm-counter";
					system-interrupts = <510 6>;
					status = "disabled";
				};

				pwm0_75: pwm0_75 {
					compatible = "infineon,cat1-pwm";
					system-interrupts = <510 6>;
					#pwm-cells = <3>;
					status = "disabled";
				};
			};

			tcpwm0_76: tcpwm0_76@40582600 {
				compatible = "infineon,tcpwm";
				reg = <0x40582600 0x80>;
				resolution = <16>;
				status = "disabled";

				counter0_76: counter0_76 {
					compatible = "infineon,tcpwm-counter";
					system-interrupts = <511 6>;
					status = "disabled";
				};

				pwm0_76: pwm0_76 {
					compatible = "infineon,cat1-pwm";
					system-interrupts = <511 6>;
					#pwm-cells = <3>;
					status = "disabled";
				};
			};

			tcpwm0_77: tcpwm0_77@40582680 {
				compatible = "infineon,tcpwm";
				reg = <0x40582680 0x80>;
				resolution = <16>;
				status = "disabled";

				counter0_77: counter0_77 {
					compatible = "infineon,tcpwm-counter";
					system-interrupts = <512 6>;
					status = "disabled";
				};

				pwm0_77: pwm0_77 {
					compatible = "infineon,cat1-pwm";
					system-interrupts = <512 6>;
					#pwm-cells = <3>;
					status = "disabled";
				};
			};

			tcpwm0_78: tcpwm0_78@40582700 {
				compatible = "infineon,tcpwm";
				reg = <0x40582700 0x80>;
				resolution = <16>;
				status = "disabled";

				counter0_78: counter0_78 {
					compatible = "infineon,tcpwm-counter";
					system-interrupts = <513 6>;
					status = "disabled";
				};

				pwm0_78: pwm0_78 {
					compatible = "infineon,cat1-pwm";
					system-interrupts = <513 6>;
					#pwm-cells = <3>;
					status = "disabled";
				};
			};

			tcpwm0_79: tcpwm0_79@40582780 {
				compatible = "infineon,tcpwm";
				reg = <0x40582780 0x80>;
				resolution = <16>;
				status = "disabled";

				counter0_79: counter0_79 {
					compatible = "infineon,tcpwm-counter";
					system-interrupts = <514 6>;
					status = "disabled";
				};

				pwm0_79: pwm0_79 {
					compatible = "infineon,cat1-pwm";
					system-interrupts = <514 6>;
					#pwm-cells = <3>;
					status = "disabled";
				};
			};

			tcpwm0_80: tcpwm0_80@40582800 {
				compatible = "infineon,tcpwm";
				reg = <0x40582800 0x80>;
				resolution = <16>;
				status = "disabled";

				counter0_80: counter0_80 {
					compatible = "infineon,tcpwm-counter";
					system-interrupts = <515 6>;
					status = "disabled";
				};

				pwm0_80: pwm0_80 {
					compatible = "infineon,cat1-pwm";
					system-interrupts = <515 6>;
					#pwm-cells = <3>;
					status = "disabled";
				};
			};

			tcpwm0_81: tcpwm0_81@40582880 {
				compatible = "infineon,tcpwm";
				reg = <0x40582880 0x80>;
				resolution = <16>;
				status = "disabled";

				counter0_81: counter0_81 {
					compatible = "infineon,tcpwm-counter";
					system-interrupts = <516 6>;
					status = "disabled";
				};

				pwm0_81: pwm0_81 {
					compatible = "infineon,cat1-pwm";
					system-interrupts = <516 6>;
					#pwm-cells = <3>;
					status = "disabled";
				};
			};

			tcpwm0_82: tcpwm0_82@40582900 {
				compatible = "infineon,tcpwm";
				reg = <0x40582900 0x80>;
				resolution = <16>;
				status = "disabled";

				counter0_82: counter0_82 {
					compatible = "infineon,tcpwm-counter";
					system-interrupts = <517 6>;
					status = "disabled";
				};

				pwm0_82: pwm0_82 {
					compatible = "infineon,cat1-pwm";
					system-interrupts = <517 6>;
					#pwm-cells = <3>;
					status = "disabled";
				};
			};

			tcpwm0_83: tcpwm0_83@40582980 {
				compatible = "infineon,tcpwm";
				reg = <0x40582980 0x80>;
				resolution = <16>;
				status = "disabled";

				counter0_83: counter0_83 {
					compatible = "infineon,tcpwm-counter";
					system-interrupts = <518 6>;
					status = "disabled";
				};

				pwm0_83: pwm0_83 {
					compatible = "infineon,cat1-pwm";
					system-interrupts = <518 6>;
					#pwm-cells = <3>;
					status = "disabled";
				};
			};

		};

		tcpwm1_grp1: tcpwm1@40588000 {
			reg = <0x40588000 0x80>;
			#address-cells = <1>;
			#size-cells = <1>;

			tcpwm1_0: tcpwm1_0@40588000 {
				compatible = "infineon,tcpwm";
				reg = <0x40588000 0x80>;
				resolution = <16>;
				status = "disabled";

				counter1_0: counter1_0 {
					compatible = "infineon,tcpwm-counter";
					system-interrupts = <522 6>;
					status = "disabled";
				};

				pwm1_0: pwm1_0 {
					compatible = "infineon,cat1-pwm";
					system-interrupts = <522 6>;
					#pwm-cells = <3>;
					status = "disabled";
				};
			};

			tcpwm1_1: tcpwm1_1@40588080 {
				compatible = "infineon,tcpwm";
				reg = <0x40588080 0x80>;
				resolution = <16>;
				status = "disabled";

				counter1_1: counter1_1 {
					compatible = "infineon,tcpwm-counter";
					system-interrupts = <523 6>;
					status = "disabled";
				};

				pwm1_1: pwm1_1 {
					compatible = "infineon,cat1-pwm";
					system-interrupts = <523 6>;
					#pwm-cells = <3>;
					status = "disabled";
				};
			};

			tcpwm1_2: tcpwm1_2@40588100 {
				compatible = "infineon,tcpwm";
				reg = <0x40588100 0x80>;
				resolution = <16>;
				status = "disabled";

				counter1_2: counter1_2 {
					compatible = "infineon,tcpwm-counter";
					system-interrupts = <524 6>;
					status = "disabled";
				};

				pwm1_2: pwm1_2 {
					compatible = "infineon,cat1-pwm";
					system-interrupts = <524 6>;
					#pwm-cells = <3>;
					status = "disabled";
				};
			};

			tcpwm1_3: tcpwm1_3@40588180 {
				compatible = "infineon,tcpwm";
				reg = <0x40588180 0x80>;
				resolution = <16>;
				status = "disabled";

				counter1_3: counter1_3 {
					compatible = "infineon,tcpwm-counter";
					system-interrupts = <525 6>;
					status = "disabled";
				};

				pwm1_3: pwm1_3 {
					compatible = "infineon,cat1-pwm";
					system-interrupts = <525 6>;
					#pwm-cells = <3>;
					status = "disabled";
				};
			};

			tcpwm1_4: tcpwm1_4@40588200 {
				compatible = "infineon,tcpwm";
				reg = <0x40588200 0x80>;
				resolution = <16>;
				status = "disabled";

				counter1_4: counter1_4 {
					compatible = "infineon,tcpwm-counter";
					system-interrupts = <526 6>;
					status = "disabled";
				};

				pwm1_4: pwm1_4 {
					compatible = "infineon,cat1-pwm";
					system-interrupts = <526 6>;
					#pwm-cells = <3>;
					status = "disabled";
				};
			};

			tcpwm1_5: tcpwm1_5@40588280 {
				compatible = "infineon,tcpwm";
				reg = <0x40588280 0x80>;
				resolution = <16>;
				status = "disabled";

				counter1_5: counter1_5 {
					compatible = "infineon,tcpwm-counter";
					system-interrupts = <527 6>;
					status = "disabled";
				};

				pwm1_5: pwm1_5 {
					compatible = "infineon,cat1-pwm";
					system-interrupts = <527 6>;
					#pwm-cells = <3>;
					status = "disabled";
				};
			};

			tcpwm1_6: tcpwm1_6@40588300 {
				compatible = "infineon,tcpwm";
				reg = <0x40588300 0x80>;
				resolution = <16>;
				status = "disabled";

				counter1_6: counter1_6 {
					compatible = "infineon,tcpwm-counter";
					system-interrupts = <528 6>;
					status = "disabled";
				};

				pwm1_6: pwm1_6 {
					compatible = "infineon,cat1-pwm";
					system-interrupts = <528 6>;
					#pwm-cells = <3>;
					status = "disabled";
				};
			};

			tcpwm1_7: tcpwm1_7@40588380 {
				compatible = "infineon,tcpwm";
				reg = <0x40588380 0x80>;
				resolution = <16>;
				status = "disabled";

				counter1_7: counter1_7 {
					compatible = "infineon,tcpwm-counter";
					system-interrupts = <529 6>;
					status = "disabled";
				};

				pwm1_7: pwm1_7 {
					compatible = "infineon,cat1-pwm";
					system-interrupts = <529 6>;
					#pwm-cells = <3>;
					status = "disabled";
				};
			};

			tcpwm1_8: tcpwm1_8@40588400 {
				compatible = "infineon,tcpwm";
				reg = <0x40588400 0x80>;
				resolution = <16>;
				status = "disabled";

				counter1_8: counter1_8 {
					compatible = "infineon,tcpwm-counter";
					system-interrupts = <530 6>;
					status = "disabled";
				};

				pwm1_8: pwm1_8 {
					compatible = "infineon,cat1-pwm";
					system-interrupts = <530 6>;
					#pwm-cells = <3>;
					status = "disabled";
				};
			};

			tcpwm1_9: tcpwm1_9@40588480 {
				compatible = "infineon,tcpwm";
				reg = <0x40588480 0x80>;
				resolution = <16>;
				status = "disabled";

				counter1_9: counter1_9 {
					compatible = "infineon,tcpwm-counter";
					system-interrupts = <531 6>;
					status = "disabled";
				};

				pwm1_9: pwm1_9 {
					compatible = "infineon,cat1-pwm";
					system-interrupts = <531 6>;
					#pwm-cells = <3>;
					status = "disabled";
				};
			};

			tcpwm1_10: tcpwm1_10@40588500 {
				compatible = "infineon,tcpwm";
				reg = <0x40588500 0x80>;
				resolution = <16>;
				status = "disabled";

				counter1_10: counter1_10 {
					compatible = "infineon,tcpwm-counter";
					system-interrupts = <532 6>;
					status = "disabled";
				};

				pwm1_10: pwm1_10 {
					compatible = "infineon,cat1-pwm";
					system-interrupts = <532 6>;
					#pwm-cells = <3>;
					status = "disabled";
				};
			};

			tcpwm1_11: tcpwm1_11@40588580 {
				compatible = "infineon,tcpwm";
				reg = <0x40588580 0x80>;
				resolution = <16>;
				status = "disabled";

				counter1_11: counter1_11 {
					compatible = "infineon,tcpwm-counter";
					system-interrupts = <533 6>;
					status = "disabled";
				};

				pwm1_11: pwm1_11 {
					compatible = "infineon,cat1-pwm";
					system-interrupts = <533 6>;
					#pwm-cells = <3>;
					status = "disabled";
				};
			};

		};

		tcpwm1_grp2: tcpwm1@40590000 {
			reg = <0x40590000 0x80>;
			#address-cells = <1>;
			#size-cells = <1>;

			tcpwm2_0: tcpwm2_0@40590000 {
				compatible = "infineon,tcpwm";
				reg = <0x40590000 0x80>;
				resolution = <32>;
				status = "disabled";

				counter2_0: counter2_0 {
					compatible = "infineon,tcpwm-counter";
					system-interrupts = <537 6>;
					status = "disabled";
				};

				pwm2_0: pwm2_0 {
					compatible = "infineon,cat1-pwm";
					system-interrupts = <537 6>;
					#pwm-cells = <3>;
					status = "disabled";
				};
			};

			tcpwm2_1: tcpwm2_1@40590080 {
				compatible = "infineon,tcpwm";
				reg = <0x40590080 0x80>;
				resolution = <32>;
				status = "disabled";

				counter2_1: counter2_1 {
					compatible = "infineon,tcpwm-counter";
					system-interrupts = <538 6>;
					status = "disabled";
				};

				pwm2_1: pwm2_1 {
					compatible = "infineon,cat1-pwm";
					system-interrupts = <538 6>;
					#pwm-cells = <3>;
					status = "disabled";
				};
			};

			tcpwm2_2: tcpwm2_2@40590100 {
				compatible = "infineon,tcpwm";
				reg = <0x40590100 0x80>;
				resolution = <32>;
				status = "disabled";

				counter2_2: counter2_2 {
					compatible = "infineon,tcpwm-counter";
					system-interrupts = <539 6>;
					status = "disabled";
				};

				pwm2_2: pwm2_2 {
					compatible = "infineon,cat1-pwm";
					system-interrupts = <539 6>;
					#pwm-cells = <3>;
					status = "disabled";
				};
			};

			tcpwm2_3: tcpwm2_3@40590180 {
				compatible = "infineon,tcpwm";
				reg = <0x40590180 0x80>;
				resolution = <32>;
				status = "disabled";

				counter2_3: counter2_3 {
					compatible = "infineon,tcpwm-counter";
					system-interrupts = <540 6>;
					status = "disabled";
				};

				pwm2_3: pwm2_3 {
					compatible = "infineon,cat1-pwm";
					system-interrupts = <540 6>;
					#pwm-cells = <3>;
					status = "disabled";
				};
			};

			tcpwm2_4: tcpwm2_4@40590200 {
				compatible = "infineon,tcpwm";
				reg = <0x40590200 0x80>;
				resolution = <32>;
				status = "disabled";

				counter2_4: counter2_4 {
					compatible = "infineon,tcpwm-counter";
					system-interrupts = <541 6>;
					status = "disabled";
				};

				pwm2_4: pwm2_4 {
					compatible = "infineon,cat1-pwm";
					system-interrupts = <541 6>;
					#pwm-cells = <3>;
					status = "disabled";
				};
			};

			tcpwm2_5: tcpwm2_5@40590280 {
				compatible = "infineon,tcpwm";
				reg = <0x40590280 0x80>;
				resolution = <32>;
				status = "disabled";

				counter2_5: counter2_5 {
					compatible = "infineon,tcpwm-counter";
					system-interrupts = <542 6>;
					status = "disabled";
				};

				pwm2_5: pwm2_5 {
					compatible = "infineon,cat1-pwm";
					system-interrupts = <542 6>;
					#pwm-cells = <3>;
					status = "disabled";
				};
			};

			tcpwm2_6: tcpwm2_6@40590300 {
				compatible = "infineon,tcpwm";
				reg = <0x40590300 0x80>;
				resolution = <32>;
				status = "disabled";

				counter2_6: counter2_6 {
					compatible = "infineon,tcpwm-counter";
					system-interrupts = <543 6>;
					status = "disabled";
				};

				pwm2_6: pwm2_6 {
					compatible = "infineon,cat1-pwm";
					system-interrupts = <543 6>;
					#pwm-cells = <3>;
					status = "disabled";
				};
			};

			tcpwm2_7: tcpwm2_7@40590380 {
				compatible = "infineon,tcpwm";
				reg = <0x40590380 0x80>;
				resolution = <32>;
				status = "disabled";

				counter2_7: counter2_7 {
					compatible = "infineon,tcpwm-counter";
					system-interrupts = <544 6>;
					status = "disabled";
				};

				pwm2_7: pwm2_7 {
					compatible = "infineon,cat1-pwm";
					system-interrupts = <544 6>;
					#pwm-cells = <3>;
					status = "disabled";
				};
			};

			tcpwm2_8: tcpwm2_8@40590400 {
				compatible = "infineon,tcpwm";
				reg = <0x40590400 0x80>;
				resolution = <32>;
				status = "disabled";

				counter2_8: counter2_8 {
					compatible = "infineon,tcpwm-counter";
					system-interrupts = <545 6>;
					status = "disabled";
				};

				pwm2_8: pwm2_8 {
					compatible = "infineon,cat1-pwm";
					system-interrupts = <545 6>;
					#pwm-cells = <3>;
					status = "disabled";
				};
			};

			tcpwm2_9: tcpwm2_9@40590480 {
				compatible = "infineon,tcpwm";
				reg = <0x40590480 0x80>;
				resolution = <32>;
				status = "disabled";

				counter2_9: counter2_9 {
					compatible = "infineon,tcpwm-counter";
					system-interrupts = <546 6>;
					status = "disabled";
				};

				pwm2_9: pwm2_9 {
					compatible = "infineon,cat1-pwm";
					system-interrupts = <546 6>;
					#pwm-cells = <3>;
					status = "disabled";
				};
			};

			tcpwm2_10: tcpwm2_10@40590500 {
				compatible = "infineon,tcpwm";
				reg = <0x40590500 0x80>;
				resolution = <32>;
				status = "disabled";

				counter2_10: counter2_10 {
					compatible = "infineon,tcpwm-counter";
					system-interrupts = <547 6>;
					status = "disabled";
				};

				pwm2_10: pwm2_10 {
					compatible = "infineon,cat1-pwm";
					system-interrupts = <547 6>;
					#pwm-cells = <3>;
					status = "disabled";
				};
			};

			tcpwm2_11: tcpwm2_11@40590580 {
				compatible = "infineon,tcpwm";
				reg = <0x40590580 0x80>;
				resolution = <32>;
				status = "disabled";

				counter2_11: counter2_11 {
					compatible = "infineon,tcpwm-counter";
					system-interrupts = <548 6>;
					status = "disabled";
				};

				pwm2_11: pwm2_11 {
					compatible = "infineon,cat1-pwm";
					system-interrupts = <548 6>;
					#pwm-cells = <3>;
					status = "disabled";
				};
			};

			tcpwm2_12: tcpwm2_12@40590600 {
				compatible = "infineon,tcpwm";
				reg = <0x40590600 0x80>;
				resolution = <32>;
				status = "disabled";

				counter2_12: counter2_12 {
					compatible = "infineon,tcpwm-counter";
					system-interrupts = <549 6>;
					status = "disabled";
				};

				pwm2_12: pwm2_12 {
					compatible = "infineon,cat1-pwm";
					system-interrupts = <549 6>;
					#pwm-cells = <3>;
					status = "disabled";
				};
			};
		};

		dma0: dw@40280000 {
			#dma-cells = <1>;
			compatible = "infineon,cat1-dma";
			reg = <0x40280000 0x10000>;
			dma-channels = <143>;
			system-interrupts = <227 6>, /* CH0 */
					    <228 6>, /* CH1 */
					    <229 6>, /* CH2 */
					    <230 6>, /* CH3 */
					    <231 6>, /* CH4 */
					    <232 6>, /* CH5 */
					    <233 6>, /* CH6 */
					    <234 6>, /* CH7 */
					    <235 6>, /* CH8 */
					    <236 6>, /* CH9 */
					    <237 6>, /* CH10 */
					    <238 6>, /* CH11 */
					    <239 6>, /* CH12 */
					    <240 6>, /* CH13 */
					    <241 6>, /* CH14 */
					    <242 6>, /* CH15 */
					    <243 6>, /* CH16 */
					    <244 6>, /* CH17 */
					    <245 6>, /* CH18 */
					    <246 6>, /* CH19 */
					    <247 6>, /* CH20 */
					    <248 6>, /* CH21 */
					    <249 6>, /* CH22 */
					    <250 6>, /* CH23 */
					    <251 6>, /* CH24 */
					    <252 6>, /* CH25 */
					    <253 6>, /* CH26 */
					    <254 6>, /* CH27 */
					    <255 6>, /* CH28 */
					    <256 6>, /* CH29 */
					    <257 6>, /* CH30 */
					    <258 6>, /* CH31 */
					    <259 6>, /* CH32 */
					    <260 6>, /* CH33 */
					    <261 6>, /* CH34 */
					    <262 6>, /* CH35 */
					    <263 6>, /* CH36 */
					    <264 6>, /* CH37 */
					    <265 6>, /* CH38 */
					    <266 6>, /* CH39 */
					    <267 6>, /* CH40 */
					    <268 6>, /* CH41 */
					    <269 6>, /* CH42 */
					    <270 6>, /* CH43 */
					    <271 6>, /* CH44 */
					    <272 6>, /* CH45 */
					    <273 6>, /* CH46 */
					    <274 6>, /* CH47 */
					    <275 6>, /* CH48 */
					    <276 6>, /* CH49 */
					    <277 6>, /* CH50 */
					    <278 6>, /* CH51 */
					    <279 6>, /* CH52 */
					    <280 6>, /* CH53 */
					    <281 6>, /* CH54 */
					    <282 6>, /* CH55 */
					    <283 6>, /* CH56 */
					    <284 6>, /* CH57 */
					    <285 6>, /* CH58 */
					    <286 6>, /* CH59 */
					    <287 6>, /* CH60 */
					    <288 6>, /* CH61 */
					    <289 6>, /* CH62 */
					    <290 6>, /* CH63 */
					    <291 6>, /* CH64 */
					    <292 6>, /* CH65 */
					    <293 6>, /* CH66 */
					    <294 6>, /* CH67 */
					    <295 6>, /* CH68 */
					    <296 6>, /* CH69 */
					    <297 6>, /* CH70 */
					    <298 6>, /* CH71 */
					    <299 6>, /* CH72 */
					    <300 6>, /* CH73 */
					    <301 6>, /* CH74 */
					    <302 6>, /* CH75 */
					    <303 6>, /* CH76 */
					    <304 6>, /* CH77 */
					    <305 6>, /* CH78 */
					    <306 6>, /* CH79 */
					    <307 6>, /* CH80 */
					    <308 6>, /* CH81 */
					    <309 6>, /* CH82 */
					    <310 6>, /* CH83 */
					    <311 6>, /* CH84 */
					    <312 6>, /* CH85 */
					    <313 6>, /* CH86 */
					    <314 6>, /* CH87 */
					    <315 6>, /* CH88 */
					    <316 6>, /* CH89 */
					    <317 6>, /* CH90 */
					    <318 6>, /* CH91 */
					    <319 6>, /* CH92 */
					    <320 6>, /* CH93 */
					    <321 6>, /* CH94 */
					    <322 6>, /* CH95 */
					    <323 6>, /* CH96 */
					    <324 6>, /* CH97 */
					    <325 6>, /* CH98 */
					    <326 6>, /* CH99 */
					    <327 6>, /* CH100 */
					    <328 6>, /* CH101 */
					    <329 6>, /* CH102 */
					    <330 6>, /* CH103 */
					    <331 6>, /* CH104 */
					    <332 6>, /* CH105 */
					    <333 6>, /* CH106 */
					    <334 6>, /* CH107 */
					    <335 6>, /* CH108 */
					    <336 6>, /* CH109 */
					    <337 6>, /* CH110 */
					    <338 6>, /* CH111 */
					    <339 6>, /* CH112 */
					    <340 6>, /* CH113 */
					    <341 6>, /* CH114 */
					    <342 6>, /* CH115 */
					    <343 6>, /* CH116 */
					    <344 6>, /* CH117 */
					    <345 6>, /* CH118 */
					    <346 6>, /* CH119 */
					    <347 6>, /* CH120 */
					    <348 6>, /* CH121 */
					    <349 6>, /* CH122 */
					    <350 6>, /* CH123 */
					    <351 6>, /* CH124 */
					    <352 6>, /* CH125 */
					    <353 6>, /* CH126 */
					    <354 6>, /* CH127 */
					    <355 6>, /* CH128 */
					    <356 6>, /* CH129 */
					    <357 6>, /* CH130 */
					    <358 6>, /* CH131 */
					    <359 6>, /* CH132 */
					    <360 6>, /* CH133 */
					    <361 6>, /* CH134 */
					    <362 6>, /* CH135 */
					    <363 6>, /* CH136 */
					    <364 6>, /* CH137 */
					    <365 6>, /* CH138 */
					    <366 6>, /* CH139 */
					    <367 6>, /* CH140 */
					    <368 6>, /* CH141 */
					    <369 6>; /* CH142 */
			status = "disabled";
		};

		dma1: dw@40290000 {
			#dma-cells = <1>;
			compatible = "infineon,cat1-dma";
			reg = <0x40290000 0x10000>;
			dma-channels = <65>;
			system-interrupts = <370 6>, /* CH0 */
					    <371 6>, /* CH1 */
					    <372 6>, /* CH2 */
					    <373 6>, /* CH3 */
					    <374 6>, /* CH4 */
					    <375 6>, /* CH5 */
					    <376 6>, /* CH6 */
					    <377 6>, /* CH7 */
					    <378 6>, /* CH8 */
					    <379 6>, /* CH9 */
					    <380 6>, /* CH10 */
					    <381 6>, /* CH11 */
					    <382 6>, /* CH12 */
					    <383 6>, /* CH13 */
					    <384 6>, /* CH14 */
					    <385 6>, /* CH15 */
					    <386 6>, /* CH16 */
					    <387 6>, /* CH17 */
					    <388 6>, /* CH18 */
					    <389 6>, /* CH19 */
					    <390 6>, /* CH20 */
					    <391 6>, /* CH21 */
					    <392 6>, /* CH22 */
					    <393 6>, /* CH23 */
					    <394 6>, /* CH24 */
					    <395 6>, /* CH25 */
					    <396 6>, /* CH26 */
					    <397 6>, /* CH27 */
					    <398 6>, /* CH28 */
					    <399 6>, /* CH29 */
					    <400 6>, /* CH30 */
					    <401 6>, /* CH31 */
					    <402 6>, /* CH32 */
					    <403 6>, /* CH33 */
					    <404 6>, /* CH34 */
					    <405 6>, /* CH35 */
					    <406 6>, /* CH36 */
					    <407 6>, /* CH37 */
					    <408 6>, /* CH38 */
					    <409 6>, /* CH39 */
					    <410 6>, /* CH40 */
					    <411 6>, /* CH41 */
					    <412 6>, /* CH42 */
					    <413 6>, /* CH43 */
					    <414 6>, /* CH44 */
					    <415 6>, /* CH45 */
					    <416 6>, /* CH46 */
					    <417 6>, /* CH47 */
					    <418 6>, /* CH48 */
					    <419 6>, /* CH49 */
					    <420 6>, /* CH50 */
					    <421 6>, /* CH51 */
					    <422 6>, /* CH52 */
					    <423 6>, /* CH53 */
					    <424 6>, /* CH54 */
					    <425 6>, /* CH55 */
					    <426 6>, /* CH56 */
					    <427 6>, /* CH57 */
					    <428 6>, /* CH58 */
					    <429 6>, /* CH59 */
					    <430 6>, /* CH60 */
					    <431 6>, /* CH61 */
					    <432 6>, /* CH62 */
					    <433 6>, /* CH63 */
					    <434 6>; /* CH64 */
			status = "disabled";
		};

		sdhc0: sdhc@40460000 {
			compatible = "infineon,cat1-sdhc-sdio";
			reg = <0x40460000 0x2000>;
			system-interrupts = <563 6>, /* SDIO wakeup interrupt for mxsdhc */
					    <562 6>; /* Consolidated interrupt for mxsdhc */
			status = "disabled";
		};
	};
};
